AUTOSAR XML (schema 4-0-3)
package /ComponentTypes
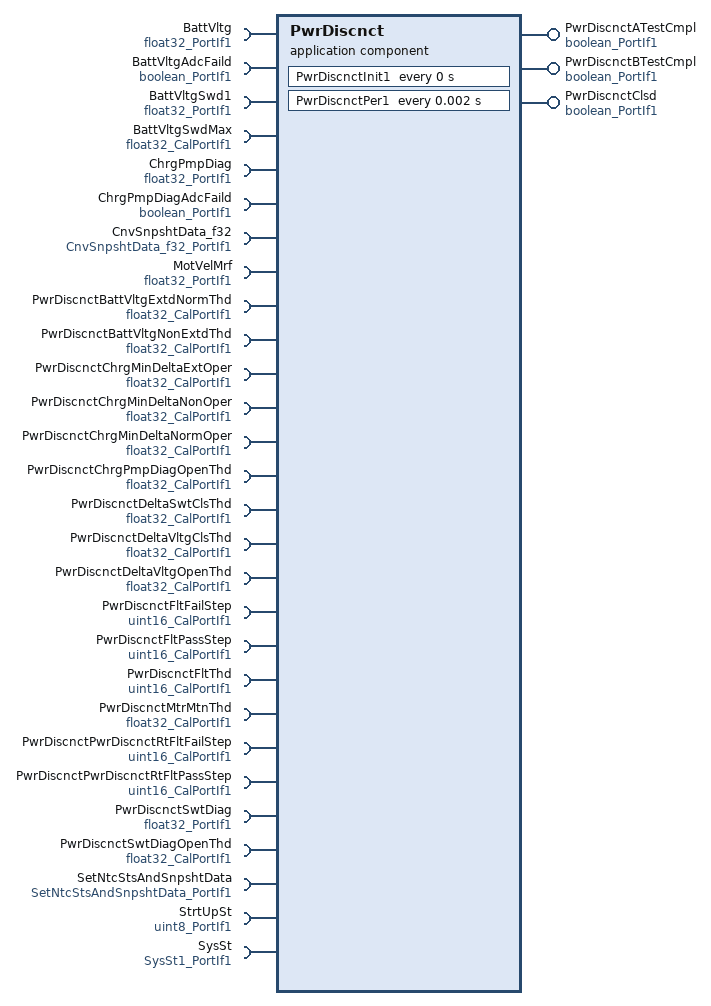
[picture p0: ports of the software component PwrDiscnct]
  application sw component type PwrDiscnct
    provide port PwrDiscnctATestCmpl: nonqueued-sender-com-spec{data-element=Logl, init-value=0}, provided-interface=boolean_PortIf1
    provide port PwrDiscnctBTestCmpl: nonqueued-sender-com-spec{data-element=Logl, init-value=0}, provided-interface=boolean_PortIf1
    provide port PwrDiscnctClsd: nonqueued-sender-com-spec{data-element=Logl, init-value=0}, provided-interface=boolean_PortIf1
    28 x require port:
      BattVltg: nonqueued-receiver-com-spec{data-element=Val, filter=data-filter-type=ALWAYS, init-value=0}, required-interface=float32_PortIf1
      BattVltgAdcFaild: nonqueued-receiver-com-spec{data-element=Logl, filter=data-filter-type=ALWAYS, init-value=0}, required-interface=boolean_PortIf1
      BattVltgSwd1: nonqueued-receiver-com-spec{data-element=Val, filter=data-filter-type=ALWAYS, init-value=0}, required-interface=float32_PortIf1
      BattVltgSwdMax: parameter-require-com-spec{init-value=16, parameter=Val}, required-interface=float32_CalPortIf1
      ChrgPmpDiag: nonqueued-receiver-com-spec{data-element=Val, filter=data-filter-type=ALWAYS, init-value=0}, required-interface=float32_PortIf1
      ChrgPmpDiagAdcFaild: nonqueued-receiver-com-spec{data-element=Logl, filter=data-filter-type=ALWAYS, init-value=0}, required-interface=boolean_PortIf1
      CnvSnpshtData_f32: client-com-spec=Oper, required-interface=CnvSnpshtData_f32_PortIf1
      MotVelMrf: nonqueued-receiver-com-spec{data-element=Val, filter=data-filter-type=ALWAYS, init-value=0}, required-interface=float32_PortIf1
      PwrDiscnctBattVltgExtdNormThd: parameter-require-com-spec{init-value=8, parameter=Val}, required-interface=float32_CalPortIf1
      PwrDiscnctBattVltgNonExtdThd: parameter-require-com-spec{init-value=7, parameter=Val}, required-interface=float32_CalPortIf1
      PwrDiscnctChrgMinDeltaExtOper: parameter-require-com-spec{init-value=5, parameter=Val}, required-interface=float32_CalPortIf1
      PwrDiscnctChrgMinDeltaNonOper: parameter-require-com-spec{init-value=0, parameter=Val}, required-interface=float32_CalPortIf1
      PwrDiscnctChrgMinDeltaNormOper: parameter-require-com-spec{init-value=6, parameter=Val}, required-interface=float32_CalPortIf1
      PwrDiscnctChrgPmpDiagOpenThd: parameter-require-com-spec{init-value=0.5, parameter=Val}, required-interface=float32_CalPortIf1
      PwrDiscnctDeltaSwtClsThd: parameter-require-com-spec{init-value=1, parameter=Val}, required-interface=float32_CalPortIf1
      PwrDiscnctDeltaVltgClsThd: parameter-require-com-spec{init-value=0.5, parameter=Val}, required-interface=float32_CalPortIf1
      PwrDiscnctDeltaVltgOpenThd: parameter-require-com-spec{init-value=2, parameter=Val}, required-interface=float32_CalPortIf1
      PwrDiscnctFltFailStep: parameter-require-com-spec{init-value=4, parameter=Val}, required-interface=uint16_CalPortIf1
      PwrDiscnctFltPassStep: parameter-require-com-spec{init-value=1, parameter=Val}, required-interface=uint16_CalPortIf1
      PwrDiscnctFltThd: parameter-require-com-spec{init-value=100, parameter=Val}, required-interface=uint16_CalPortIf1
      PwrDiscnctMtrMtnThd: parameter-require-com-spec{init-value=100, parameter=Val}, required-interface=float32_CalPortIf1
      PwrDiscnctPwrDiscnctRtFltFailStep: parameter-require-com-spec{init-value=1308, parameter=Val}, required-interface=uint16_CalPortIf1
      PwrDiscnctPwrDiscnctRtFltPassStep: parameter-require-com-spec{init-value=327, parameter=Val}, required-interface=uint16_CalPortIf1
      PwrDiscnctSwtDiag: nonqueued-receiver-com-spec{data-element=Val, filter=data-filter-type=ALWAYS, init-value=0}, required-interface=float32_PortIf1
      PwrDiscnctSwtDiagOpenThd: parameter-require-com-spec{init-value=0.5, parameter=Val}, required-interface=float32_CalPortIf1
      SetNtcStsAndSnpshtData: client-com-spec=Oper, required-interface=SetNtcStsAndSnpshtData_PortIf1
      StrtUpSt: nonqueued-receiver-com-spec{data-element=Val, filter=data-filter-type=ALWAYS, init-value=0}, required-interface=uint8_PortIf1
      SysSt: nonqueued-receiver-com-spec{data-element=Val, filter=data-filter-type=ALWAYS, init-value=3}, required-interface=SysSt1_PortIf1
    behavior PwrDiscnct_InternalBehavior
      ar-typed-per-instance-memorys:
        7 x data, all with sw-calibration-access=READ-ONLY:
          FirstRunCmpl: type=boolean
          Ntc042PrmByte: type=uint8
          PwrDiscnctClsdSts: type=boolean
          PwrDiscnctFltAtInitErrAcc: type=uint16
          PwrDiscnctSt: type=PwrDiscnctSts1
          PwrDiscnctTestACmpl: type=boolean
          PwrDiscnctTestBCmpl: type=boolean
      timing event PwrDiscnct_InitEvent: start-on-event=PwrDiscnctInit1, period=0
      timing event TMT_PwrDiscnctPer1: start-on-event=PwrDiscnctPer1, period=0.002
      port-api-options:
        enable-take-address=false, indirect-api=false, port=BattVltg
        enable-take-address=false, indirect-api=false, port=BattVltgAdcFaild
        enable-take-address=false, indirect-api=false, port=BattVltgSwd1
        enable-take-address=false, indirect-api=false, port=ChrgPmpDiag
        enable-take-address=false, indirect-api=false, port=ChrgPmpDiagAdcFaild
        enable-take-address=false, indirect-api=false, port=CnvSnpshtData_f32
        enable-take-address=false, indirect-api=false, port=MotVelMrf
        enable-take-address=false, indirect-api=false, port=PwrDiscnctATestCmpl
        enable-take-address=false, indirect-api=false, port=PwrDiscnctBattVltgExtdNormThd
        enable-take-address=false, indirect-api=false, port=PwrDiscnctBattVltgNonExtdThd
        enable-take-address=false, indirect-api=false, port=PwrDiscnctBTestCmpl
        enable-take-address=false, indirect-api=false, port=PwrDiscnctChrgMinDeltaExtOper
        enable-take-address=false, indirect-api=false, port=PwrDiscnctChrgMinDeltaNonOper
        enable-take-address=false, indirect-api=false, port=PwrDiscnctChrgMinDeltaNormOper
        enable-take-address=false, indirect-api=false, port=PwrDiscnctChrgPmpDiagOpenThd
        enable-take-address=false, indirect-api=false, port=PwrDiscnctClsd
        enable-take-address=false, indirect-api=false, port=PwrDiscnctDeltaSwtClsThd
        enable-take-address=false, indirect-api=false, port=PwrDiscnctDeltaVltgClsThd
        enable-take-address=false, indirect-api=false, port=PwrDiscnctFltFailStep
        enable-take-address=false, indirect-api=false, port=PwrDiscnctFltPassStep
        enable-take-address=false, indirect-api=false, port=PwrDiscnctFltThd
        enable-take-address=false, indirect-api=false, port=PwrDiscnctMtrMtnThd
        enable-take-address=false, indirect-api=false, port=PwrDiscnctPwrDiscnctRtFltFailStep
        enable-take-address=false, indirect-api=false, port=PwrDiscnctSwtDiag
        enable-take-address=false, indirect-api=false, port=PwrDiscnctSwtDiagOpenThd
        enable-take-address=false, indirect-api=false, port=SetNtcStsAndSnpshtData
        enable-take-address=false, indirect-api=false, port=StrtUpSt
        enable-take-address=false, indirect-api=false, port=SysSt
      runnable PwrDiscnctInit1
      runnable PwrDiscnctPer1
        data-receive-point-by-arguments:
          9 x access:
            REC_BattVltg_Val: accessed-variable=BattVltg.Val
            REC_BattVltgAdcFaild_Logl: accessed-variable=BattVltgAdcFaild.Logl
            REC_BattVltgSwd1_Val: accessed-variable=BattVltgSwd1.Val
            REC_ChrgPmpDiag_Val: accessed-variable=ChrgPmpDiag.Val
            REC_ChrgPmpDiagAdcFaild_Logl: accessed-variable=ChrgPmpDiagAdcFaild.Logl
            REC_MotVelMrf_Val: accessed-variable=MotVelMrf.Val
            REC_PwrDiscnctSwtDiag_Val: accessed-variable=PwrDiscnctSwtDiag.Val
            REC_StrtUpSt_Val: accessed-variable=StrtUpSt.Val
            REC_SysSt_Val: accessed-variable=SysSt.Val
        data-send-points:
          access SEND_PwrDiscnctATestCmpl_Logl: accessed-variable=PwrDiscnctATestCmpl.Logl
          access SEND_PwrDiscnctBTestCmpl_Logl: accessed-variable=PwrDiscnctBTestCmpl.Logl
          access SEND_PwrDiscnctClsd_Logl: accessed-variable=PwrDiscnctClsd.Logl
        sync call SC_CnvSnpshtData_f32_Oper: operation=CnvSnpshtData_f32.Oper, timeout=0
        sync call SC_SetNtcStsAndSnpshtData_Oper: operation=SetNtcStsAndSnpshtData.Oper, timeout=0
  swc implementation PwrDiscnct_Implementation: behavior=PwrDiscnct_InternalBehavior
    code-descriptors:
      code Default: artifact-descriptors=autosar-engineering-object={short-label=Default, category=SWSRC}
